# PIC32CM5112GC00048 device description
Architecture: CORTEX-M23; Family: PIC32CM; Series: PIC32CMGC00
Registers are 32-bit, read-write, reset 0x0 unless marked. A register's access mark holds for its fields unless they carry their own. Offsets are from the block's base; [hi:lo] are bit positions; {n}, {i} and the like mark numbered series; <NAME> marks a mode.

## FPB — Flash Patch and Breakpoint
Instances: FPB 0xE0002000
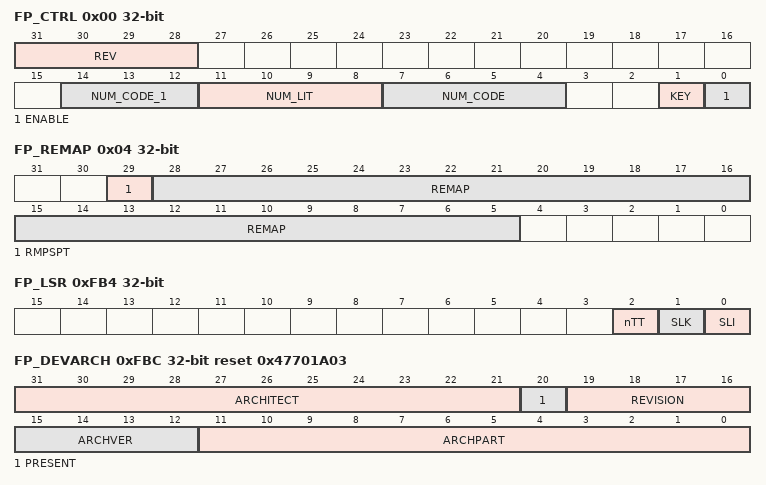
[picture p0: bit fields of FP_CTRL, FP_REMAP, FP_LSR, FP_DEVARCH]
0x00 FP_CTRL reset not defined — Flash Patch Control Register
  [31:28] REV — Revision
  [14:12] NUM_CODE_1 — Number of implemented code comparators bits [6:4]
  [11:8] NUM_LIT — Number of literal comparators
  [7:4] NUM_CODE — Number of implemented code comparators bits [3:0]
  [1] KEY — FP_CTRL write-enable key
  [0] ENABLE — Flash Patch global enable
0x04 FP_REMAP ro reset not defined — Flash Patch Remap Register
  [29] RMPSPT — Remap supported
  [28:5] REMAP — Remap address
{0x8+4i} FP_COMP[{i}] (i=0..3) reset not defined — Flash Patch Comparator Register n
  [0] BE — Breakpoint enable
  [31:1] BPADDR <BREAKPOINT> — Breakpoint address
  [31] FE <DEFAULT> — Flash Patch enable
  [28:2] FPADDR <DEFAULT> — Flash Patch address
0xFB0 FP_LAR wo reset not defined — FPB Software Lock Access Register
  [31:0] KEY — Lock access control
    0xC5ACCE55=UNLOCK (Unlock key value)
0xFB4 FP_LSR ro reset not defined — FPB Software Lock Status Register
  [2] nTT — Not thirty-two bit
  [1] SLK — Software Lock status
  [0] SLI — Software Lock implemented
0xFBC FP_DEVARCH ro reset 0x47701A03 — FPB Device Architecture Register
  [31:21] ARCHITECT
  [20] PRESENT — DEVARCH Present
  [19:16] REVISION
  [15:12] ARCHVER — Architecture Version
  [11:0] ARCHPART — Architecture Part
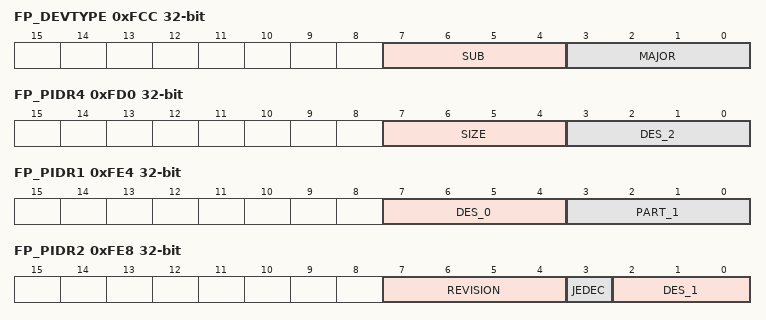
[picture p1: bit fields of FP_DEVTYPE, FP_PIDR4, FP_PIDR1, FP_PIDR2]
0xFCC FP_DEVTYPE ro — FPB Device Type Register
  [7:4] SUB — Sub-type
  [3:0] MAJOR — Major type
0xFD0 FP_PIDR4 ro reset not defined — FP Peripheral Identification Register 4
  [7:4] SIZE — 4KB count
  [3:0] DES_2 — JEP106 continuation code
{0xFC0+4i} FP_PIDR{i} ro (i=5..7) — FP Peripheral Identification Register {i}
0xFE0 FP_PIDR0 ro reset not defined — FP Peripheral Identification Register 0
  [7:0] PART_0 — Part number bits[7:0]
0xFE4 FP_PIDR1 ro reset not defined — FP Peripheral Identification Register 1
  [7:4] DES_0 — JEP106 identification code bits [3:0]
  [3:0] PART_1 — Part number bits[11:8]
0xFE8 FP_PIDR2 ro reset not defined — FP Peripheral Identification Register 2
  [7:4] REVISION — Component revision
  [3] JEDEC — JEDEC assignee value is used
  [2:0] DES_1 — JEP106 identification code bits[6:4]
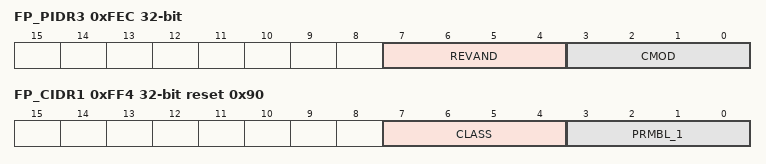
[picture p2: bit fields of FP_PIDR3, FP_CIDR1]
0xFEC FP_PIDR3 ro reset not defined — FP Peripheral Identification Register 3
  [7:4] REVAND
  [3:0] CMOD — Customer Modified
0xFF0 FP_CIDR0 ro reset 0xD — FP Component Identification Register 0
  [7:0] PRMBL_0 — CoreSight component identification preamble
0xFF4 FP_CIDR1 ro reset 0x90 — FP Component Identification Register 1
  [7:4] CLASS — CoreSight component class
  [3:0] PRMBL_1 — CoreSight component identification preamble
0xFF8 FP_CIDR2 ro reset 0x5 — FP Component Identification Register 2
  [7:0] PRMBL_2 — CoreSight component identification preamble
0xFFC FP_CIDR3 ro reset 0xB1 — FP Component Identification Register 3
  [7:0] PRMBL_3 — CoreSight component identification preamble

## FREQM — Frequency Meter
Instances: FREQM 0x4400C000
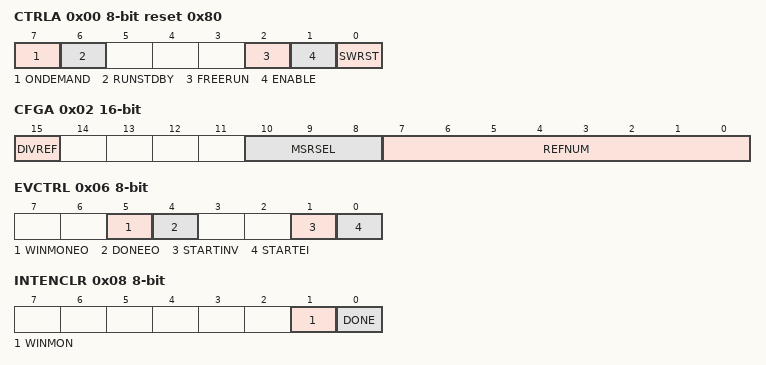
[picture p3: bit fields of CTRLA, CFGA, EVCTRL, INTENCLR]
0x00 CTRLA 8-bit reset 0x80 — Control A Register
  [7] ONDEMAND — On Demand Control
  [6] RUNSTDBY — Run In Standby
  [2] FREERUN — Free Running Mode
  [1] ENABLE
  [0] SWRST — Software Reset
0x01 CTRLB 8-bit wo — Control B Register
  [0] START — Start Measurement
0x02 CFGA 16-bit — Config A Register
  [15] DIVREF — Divide Reference Clock
    0=DIV1 (The reference clock is divided by 1); 1=DIV8 (The reference clock is divided by 8)
  [10:8] MSRSEL — Measurement Clock Selection
    0=GCLK (GCLK Input Clock); 1=CPU (CPU Input Clock)
  [7:0] REFNUM — Number of Reference Clock Cycles
0x04 CTRLC 8-bit — Control C Register
  [2:0] WINMODE — Window Monitor Mode
    0=DISABLE (No window mode (default)); 1=MODE1 (VALUE > WINLT); 2=MODE2 (VALUE < WINUT); 3=MODE3 (WINLT < VALUE < WINUT); 4=MODE4 (!(WINLT < VALUE < WINUT))
0x06 EVCTRL 8-bit — Event Control Register
  [5] WINMONEO — Window Monitor Event Out
  [4] DONEEO — Measurement Done Event Out
  [1] STARTINV — Start Measurement Event Invert Enable
  [0] STARTEI — Start Measurement Event Input Enable
0x08 INTENCLR 8-bit (atomic clear) — Interrupt Enable Clear Register
  [1] WINMON — Window Monitor Interrupt Disable
  [0] DONE — Measurement Done Interrupt Disable
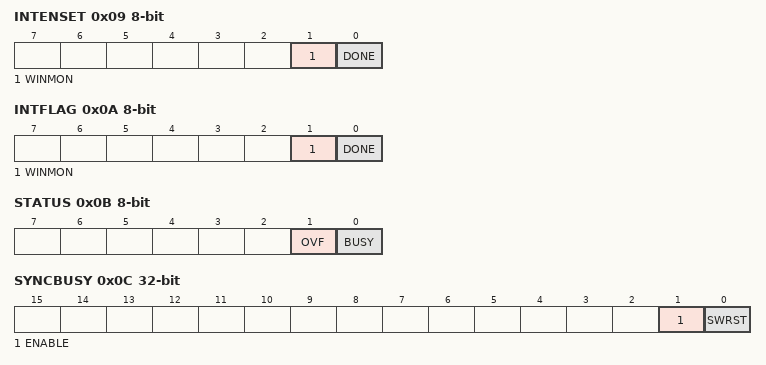
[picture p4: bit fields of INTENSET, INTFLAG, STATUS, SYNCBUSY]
0x09 INTENSET 8-bit (atomic set) — Interrupt Enable Set Register
  [1] WINMON — Window Monitor Interrupt Enable
  [0] DONE — Measurement Done Interrupt Enable
0x0A INTFLAG 8-bit (atomic clear) — Interrupt Flag Register
  [1] WINMON — Window Monitor
  [0] DONE — Measurement Done
0x0B STATUS 8-bit
  [1] OVF — Sticky Count Value Overflow
  [0] BUSY — FREQM Status
0x0C SYNCBUSY ro — Synchronization Busy Register
  [1] ENABLE
  [0] SWRST — Software Reset
0x10 VALUE ro — Count Value Register
  [23:0] VALUE — Measurement Value
0x20 WINLT — Window Monitor Lower Threshold
  [23:0] WINLT — Window Lower Threshold
0x24 WINUT — Window Monitor Upper Threshold
  [23:0] WINUT — Window Upper Threshold

## Notices in the file
Copyright (c) 2024 Microchip Technology Inc.
SPDX-License-Identifier: Apache-2.0
Licensed under the Apache License, Version 2.0 (the "License");
you may not use this file except in compliance with the License.
You may obtain a copy of the License at
http://www.apache.org/licenses/LICENSE-2.0
Unless required by applicable law or agreed to in writing, software
distributed under the License is distributed on an "AS IS" BASIS,
WITHOUT WARRANTIES OR CONDITIONS OF ANY KIND, either express or implied.
See the License for the specific language governing permissions and
limitations under the License.
